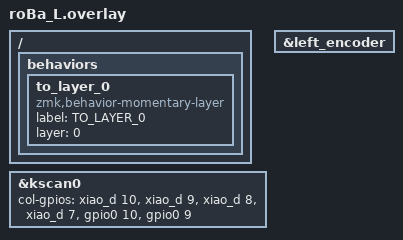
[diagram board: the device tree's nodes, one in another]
#include "roBa.dtsi"

&kscan0 {
        col-gpios
            = <&xiao_d 10 GPIO_ACTIVE_HIGH>
            , <&xiao_d 9 GPIO_ACTIVE_HIGH> 
            , <&xiao_d 8 GPIO_ACTIVE_HIGH> 
            , <&xiao_d 7 GPIO_ACTIVE_HIGH> 
            , <&gpio0 10 GPIO_ACTIVE_HIGH>
            , <&gpio0 9 GPIO_ACTIVE_HIGH>
            ;
};

&left_encoder {
    status = "okay";
};

/ {
    behaviors {
        to_layer_0: to_layer_0 {
            compatible = "zmk,behavior-momentary-layer";
            label = "TO_LAYER_0";
            layer = <0>;
        };
    };
};
